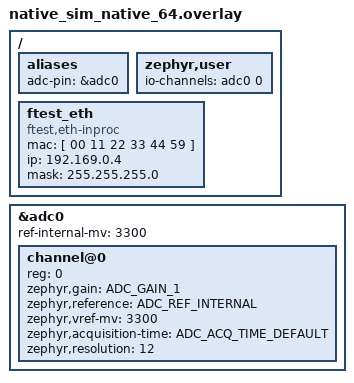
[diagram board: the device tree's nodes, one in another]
/ {
    aliases {
        adc-pin = &adc0;
    };

    zephyr,user {
        io-channels = <&adc0 0>;
    };

    ftest_eth: ftest_eth {
        compatible = "ftest,eth-inproc";
        mac = [ 00 11 22 33 44 59  ];
        ip = "192.169.0.4";
        mask = "255.255.255.0";
    };
};

&adc0 {
    status = "okay";
    #address-cells = <1>;
    #size-cells = <0>;
    ref-internal-mv = <3300>;

    channel@0 {
        reg = <0>;
        zephyr,gain = "ADC_GAIN_1";
        zephyr,reference = "ADC_REF_INTERNAL";
        zephyr,vref-mv = <3300>;
        zephyr,acquisition-time = <ADC_ACQ_TIME_DEFAULT>;
        zephyr,resolution = <12>;
    };
};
